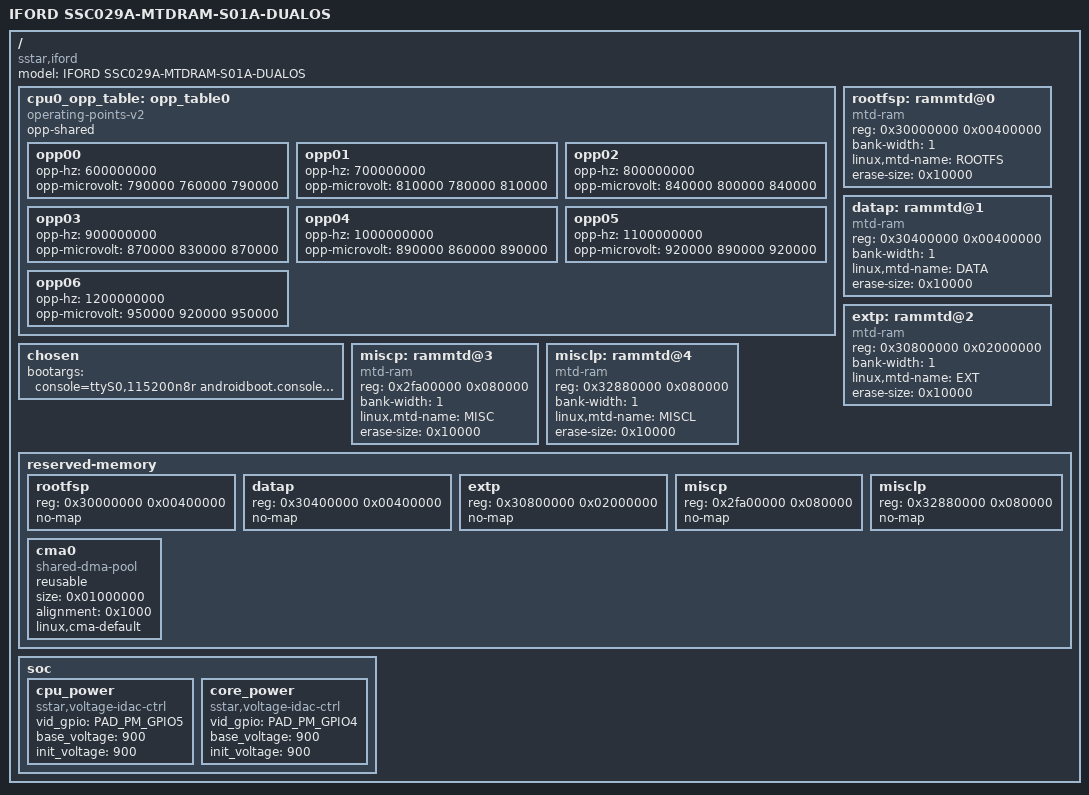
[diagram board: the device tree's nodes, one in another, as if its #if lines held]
/*
* iford-ssc029a-mtdram-s01a-dualos.dts- Sigmastar
*
* Copyright (c) [2019~2020] SigmaStar Technology.
*
*
* This software is licensed under the terms of the GNU General Public
* License version 2, as published by the Free Software Foundation, and
* may be copied, distributed, and modified under those terms.
*
* This program is distributed in the hope that it will be useful,
* but WITHOUT ANY WARRANTY; without even the implied warranty of
* MERCHANTABILITY or FITNESS FOR A PARTICULAR PURPOSE.  See the
* GNU General Public License version 2 for more details.
*
*/

 /*
 * Memory Layout
 * 0x20000000-0x24000000 64M Kernel
 * 0x24000000-0x24800000 8M  system
 * 0x24800000-0x24900000 1M  data
 * 0x24900000-0x25000000 7M  temp0
 * 0x25000000-0x28000000 48M temp1
 */
/dts-v1/;

#include "iford.dtsi"
#include "iford-ssc029a-s01a-padmux.dtsi"

/ {
    #address-cells = <1>;
    #size-cells = <1>;
    model = "IFORD SSC029A-MTDRAM-S01A-DUALOS";
    compatible = "sstar,iford";
/*
    memory {
        device_type = "memory";
        #address-cells = <2>;
        #size-cells = <2>;
        reg = <0x00000000 0x20000000 0x00000000 0x04000000>;
    };
    chosen {
        bootargs = "console=ttyS0,115200n8r androidboot.console=ttyS0 user_debug=31 root=/dev/mtdblock0 init=/linuxrc LX_MEM=0x04000000 mma_heap=mma_heap_name0,miu=0,sz=0xA000000,max_start_off=0x29800000 mma_memblock_remove=1 cma=2M nohz=off";
    };
*/
#if IS_ENABLED(CONFIG_SSTAR_VOLTAGE_IDAC_CTRL)
    cpu0_opp_table: opp_table0 {
        compatible = "operating-points-v2";
        opp-shared;

        opp00 {
            opp-hz = /bits/ 64 <600000000>;
            opp-microvolt = <790000 760000 790000>; /* <normal min max> */
            status = "ok";
        };

        opp01 {
            opp-hz = /bits/ 64 <700000000>;
            opp-microvolt = <810000 780000 810000>; /* <normal min max> */
            status = "ok";
        };

        opp02 {
            opp-hz = /bits/ 64 <800000000>;
            opp-microvolt = <840000 800000 840000>; /* <normal min max> */
            status = "ok";
        };

        opp03 {
            opp-hz = /bits/ 64 <900000000>;
            opp-microvolt = <870000 830000 870000>; /* <normal min max> */
            status = "ok";
        };

        opp04 {
            opp-hz = /bits/ 64 <1000000000>;
            opp-microvolt = <890000 860000 890000>;
            status = "ok";
        };

        opp05 {
            opp-hz = /bits/ 64 <1100000000>;
            opp-microvolt = <920000 890000 920000>;
            status = "ok";
        };

        opp06 {
            opp-hz = /bits/ 64 <1200000000>;
            opp-microvolt = <950000 920000 950000>;
            status = "ok";
        };
    };
#endif
    chosen {
        bootargs = "console=ttyS0,115200n8r androidboot.console=ttyS0 user_debug=31 root=/dev/ram rdinit=/linuxrc initrd=0x20e00000,0x100000 rootwait LX_MEM=0x04000000 mma_heap=mma_heap_name0,miu=0,sz=0xA000000,max_start_off=0x29800000 mma_memblock_remove=1 cma=2M nohz=off";
    };

    rootfsp:rammtd@0 {
        compatible = "mtd-ram";
        reg= <0x30000000 0x00400000>;
        bank-width = <1>;
        linux,mtd-name = "ROOTFS";
        erase-size = <0x10000>;
    };
    /* Size of this partition must be identical to the size of data.jffs2 due to JFFS2 limitation */
    datap:rammtd@1 {
        compatible = "mtd-ram";
        reg= <0x30400000 0x00400000>;
        bank-width = <1>;
        linux,mtd-name = "DATA";
        erase-size = <0x10000>;
    };

    extp:rammtd@2 {
        compatible = "mtd-ram";
        reg= <0x30800000 0x02000000>;
        bank-width = <1>;
        linux,mtd-name = "EXT";
        erase-size = <0x10000>;
    };
    miscp:rammtd@3 {
        compatible = "mtd-ram";
        reg= <0x2fa00000 0x080000>;
        bank-width = <1>;
        linux,mtd-name = "MISC";
        erase-size = <0x10000>;
    };
    misclp:rammtd@4 {
        compatible = "mtd-ram";
        reg= <0x32880000 0x080000>;
        bank-width = <1>;
        linux,mtd-name = "MISCL";
        erase-size = <0x10000>;
    };
/*!!IMPORTANT!! The reserved memory must be 1MB aligned*/
    reserved-memory {
        #address-cells = <1>;
        #size-cells = <1>;
        ranges;

        rootfsp {
            reg= <0x30000000 0x00400000>;
            no-map;
        };
        datap {
            reg= <0x30400000 0x00400000>;
            no-map;
        };
        extp {
            reg= <0x30800000 0x02000000>;
            no-map;
        };
        miscp {
            reg= <0x2fa00000 0x080000>;
            no-map;
        };
        misclp {
            reg= <0x32880000 0x080000>;
            no-map;
        };
        cma0 {
            compatible = "shared-dma-pool";
            reusable;
            size = <0x01000000>;
            alignment = <0x1000>;
            linux,cma-default;
        };
    };

#if IS_ENABLED(CONFIG_SSTAR_VOLTAGE_IDAC_CTRL)
    soc {
#if IS_ENABLED(CONFIG_SSTAR_CPUFREQ_DVS)
        cpu_power {
            compatible = "sstar,voltage-idac-ctrl";
            vid_gpio = <PAD_PM_GPIO5>;
            base_voltage = <900>;
            init_voltage = <900>;
            status = "ok";
        };
#endif
        core_power {
            compatible = "sstar,voltage-idac-ctrl";
            vid_gpio = <PAD_PM_GPIO4>;
            base_voltage = <900>;
            init_voltage = <900>;
            status = "ok";
        };
    };
#endif
};
